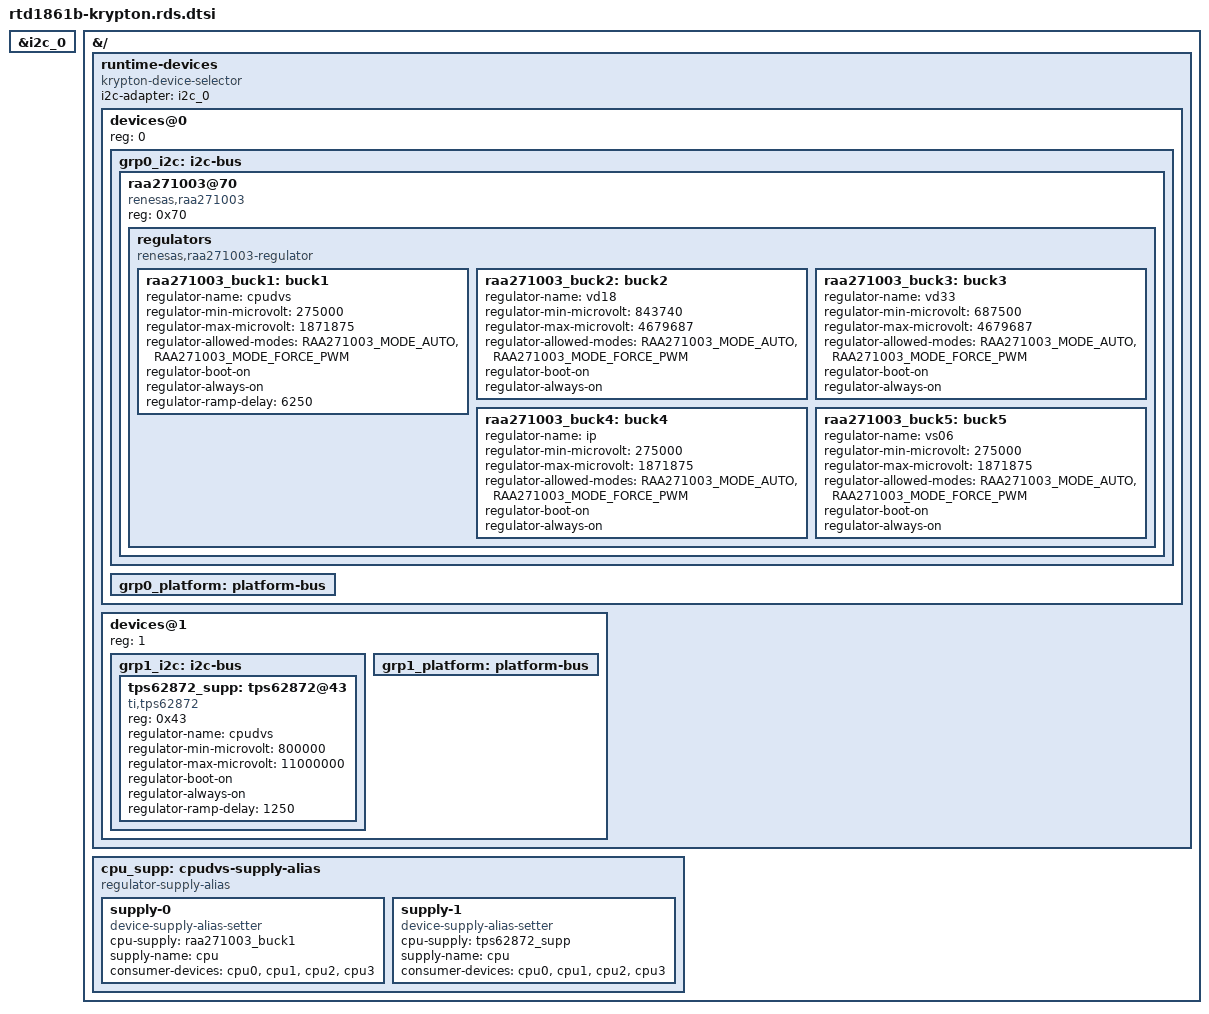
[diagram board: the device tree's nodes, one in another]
#include <dt-bindings/regulator/raa271003-regulator.h>

&i2c_0 {
	status = "okay";
};

&{/} {
	runtime-devices {
		compatible = "krypton-device-selector";
		#size-cells = <0>;
		#address-cells = <1>;
		i2c-adapter = <&i2c_0>;

		devices@0 {
			reg = <0>;

			grp0_i2c: i2c-bus {
				#size-cells = <0>;
				#address-cells = <1>;
			};

			grp0_platform: platform-bus {
			};
		};

		devices@1 {
			reg = <1>;

			grp1_i2c: i2c-bus {
				#size-cells = <0>;
				#address-cells = <1>;
			};

			grp1_platform: platform-bus {
			};
		};
	};
};

&grp0_i2c {
	raa271003@70 {
		compatible = "renesas,raa271003";
		reg = <0x70>;

		regulators {
			compatible = "renesas,raa271003-regulator";

			raa271003_buck1: buck1 {
				regulator-name = "cpudvs";
				regulator-min-microvolt = <275000>;
				regulator-max-microvolt = <1871875>;
				regulator-allowed-modes = <RAA271003_MODE_AUTO>,
							  <RAA271003_MODE_FORCE_PWM>;
				regulator-boot-on;
				regulator-always-on;
				regulator-ramp-delay = <6250>;
			};

			raa271003_buck2: buck2 {
				regulator-name = "vd18";
				regulator-min-microvolt = <843740>;
				regulator-max-microvolt = <4679687>;
				regulator-allowed-modes = <RAA271003_MODE_AUTO>,
							  <RAA271003_MODE_FORCE_PWM>;
				regulator-boot-on;
				regulator-always-on;
			};

			raa271003_buck3: buck3 {
				regulator-name = "vd33";
				regulator-min-microvolt = <687500>;
				regulator-max-microvolt = <4679687>;
				regulator-allowed-modes = <RAA271003_MODE_AUTO>,
							  <RAA271003_MODE_FORCE_PWM>;
				regulator-boot-on;
				regulator-always-on;
			};

			raa271003_buck4: buck4 {
				regulator-name = "ip";
				regulator-min-microvolt = <275000>;
				regulator-max-microvolt = <1871875>;
				regulator-allowed-modes = <RAA271003_MODE_AUTO>,
							  <RAA271003_MODE_FORCE_PWM>;
				regulator-boot-on;
				regulator-always-on;
			};
			raa271003_buck5: buck5 {
				regulator-name = "vs06";
				regulator-min-microvolt = <275000>;
				regulator-max-microvolt = <1871875>;
				regulator-allowed-modes = <RAA271003_MODE_AUTO>,
							  <RAA271003_MODE_FORCE_PWM>;
				regulator-boot-on;
				regulator-always-on;
			};
		};
	};
};

&grp1_i2c {
	tps62872_supp: tps62872@43 {
		compatible = "ti,tps62872";
		reg = <0x43>;
		regulator-name = "cpudvs";
		regulator-min-microvolt = <800000>;
		regulator-max-microvolt = <11000000>;
		regulator-boot-on;
		regulator-always-on;
		regulator-ramp-delay = <1250>;
	};
};

&{/} {
	cpu_supp: cpudvs-supply-alias {
		compatible = "regulator-supply-alias";

		supply-0 {
			compatible = "device-supply-alias-setter";
			cpu-supply = <&raa271003_buck1>;
			supply-name = "cpu";
			consumer-devices = <&cpu0>, <&cpu1>, <&cpu2>, <&cpu3>;
		};

		supply-1 {
			compatible = "device-supply-alias-setter";
			cpu-supply = <&tps62872_supp>;
			supply-name = "cpu";
			consumer-devices = <&cpu0>, <&cpu1>, <&cpu2>, <&cpu3>;
		};
	};
};
